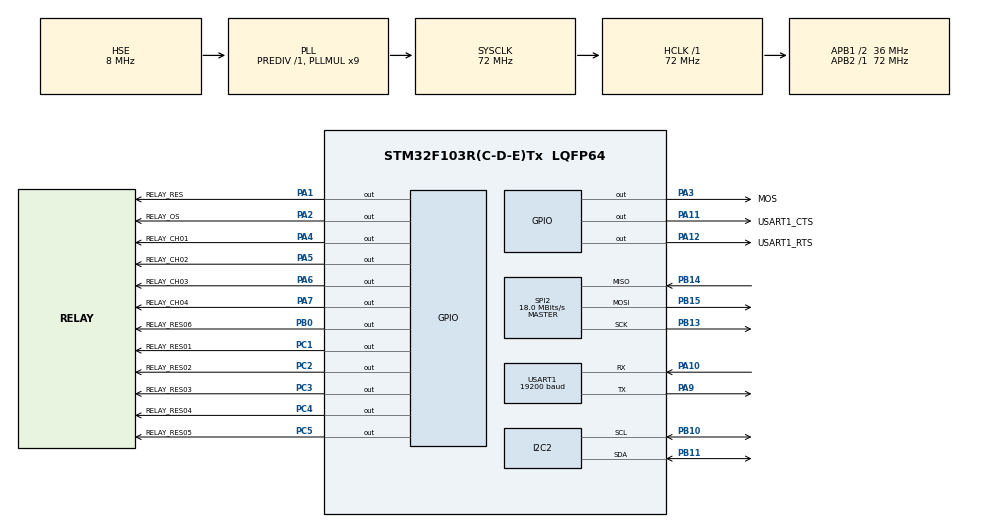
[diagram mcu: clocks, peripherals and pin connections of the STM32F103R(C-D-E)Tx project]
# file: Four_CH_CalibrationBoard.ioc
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Mcu.Family=STM32F1
Mcu.Name=STM32F103R(C-D-E)Tx
Mcu.Package=LQFP64
NVIC.PriorityGroup=NVIC_PRIORITYGROUP_4
NVIC.TIM7_IRQn=true\:0\:0\:false\:false\:true\:true\:true\:true
NVIC.USART1_IRQn=true\:0\:0\:false\:false\:true\:true\:true\:true
PA1.GPIO_Label=RELAY_RES 
PA1.GPIO_PuPd=GPIO_NOPULL
PA1.PinState=GPIO_PIN_SET
PA1.Signal=GPIO_Output
PA10.Mode=Asynchronous
PA10.Signal=USART1_RX
PA11.GPIO_Label=USART1_CTS
PA11.Signal=GPIO_Output
PA12.GPIO_Label=USART1_RTS
PA12.Signal=GPIO_Output
PA13.Mode=Serial_Wire
PA13.Signal=SYS_JTMS-SWDIO
PA14.Mode=Serial_Wire
PA14.Signal=SYS_JTCK-SWCLK
PA2.GPIO_Label=RELAY_OS 
PA2.Signal=GPIO_Output
PA3.GPIO_Label=MOS 
PA3.Signal=GPIO_Output
PA4.GPIO_Label=RELAY_CH01 
PA4.Signal=GPIO_Output
PA5.GPIO_Label=RELAY_CH02 
PA5.Signal=GPIO_Output
PA6.GPIO_Label=RELAY_CH03 
PA6.Signal=GPIO_Output
PA7.GPIO_Label=RELAY_CH04 
PA7.Signal=GPIO_Output
PA9.Mode=Asynchronous
PA9.Signal=USART1_TX
PB0.GPIO_Label=RELAY_RES06 
PB0.Signal=GPIO_Output
PB10.Mode=I2C
PB10.Signal=I2C2_SCL
PB11.Mode=I2C
PB11.Signal=I2C2_SDA
PB13.Mode=Full_Duplex_Master
PB13.Signal=SPI2_SCK
PB14.Mode=Full_Duplex_Master
PB14.Signal=SPI2_MISO
PB15.Mode=Full_Duplex_Master
PB15.Signal=SPI2_MOSI
PC1.GPIO_Label=RELAY_RES01 
PC1.Signal=GPIO_Output
PC2.GPIO_Label=RELAY_RES02 
PC2.Signal=GPIO_Output
PC3.GPIO_Label=RELAY_RES03 
PC3.Signal=GPIO_Output
PC4.GPIO_Label=RELAY_RES04
PC4.Signal=GPIO_Output
PC5.GPIO_Label=RELAY_RES05
PC5.Signal=GPIO_Output
PD0-OSC_IN.Mode=HSE-External-Oscillator
PD0-OSC_IN.Signal=RCC_OSC_IN
PD1-OSC_OUT.Mode=HSE-External-Oscillator
PD1-OSC_OUT.Signal=RCC_OSC_OUT
ProjectManager.HeapSize=0x200
ProjectManager.StackSize=0x400
ProjectManager.TargetToolchain=STM32CubeIDE
RCC.AHBFreq_Value=72000000
RCC.APB1CLKDivider=RCC_HCLK_DIV2
RCC.APB1Freq_Value=36000000
RCC.APB1TimFreq_Value=72000000
RCC.APB2Freq_Value=72000000
RCC.APB2TimFreq_Value=72000000
RCC.HCLKFreq_Value=72000000
RCC.PLLMUL=RCC_PLL_MUL9
RCC.PLLSourceVirtual=RCC_PLLSOURCE_HSE
RCC.SYSCLKFreq_VALUE=72000000
RCC.SYSCLKSource=RCC_SYSCLKSOURCE_PLLCLK
RCC.USBFreq_Value=72000000
SPI2.CalculateBaudRate=18.0 MBits/s
SPI2.Direction=SPI_DIRECTION_2LINES
SPI2.Mode=SPI_MODE_MASTER
SPI2.VirtualType=VM_MASTER
TIM7.AutoReloadPreload=TIM_AUTORELOAD_PRELOAD_ENABLE
USART1.BaudRate=19200
USART1.Parity=PARITY_EVEN
USART1.VirtualMode=VM_ASYNC
USART1.WordLength=WORDLENGTH_9B
VP_TIM7_VS_ClockSourceINT.Mode=Enable_Timer
board=custom

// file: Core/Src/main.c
/* USER CODE BEGIN Header */
/**
  ******************************************************************************
  * @file           : main.c
  * @brief          : Main program body
  ******************************************************************************
  * @attention
  *
  * Copyright (c) 2025 STMicroelectronics.
  * All rights reserved.
  *
  * This software is licensed under terms that can be found in the LICENSE file
  * in the root directory of this software component.
  * If no LICENSE file comes with this software, it is provided AS-IS.
  *
  ******************************************************************************
  */
/* USER CODE END Header */
#include "main.h"
#include "i2c.h"
#include "spi.h"
#include "tim.h"
#include "usart.h"
#include "gpio.h"

/* USER CODE BEGIN Includes */
#include "mb.h"
#include "command.h"
#include "hc_smu_control.h"

/* USER CODE END Includes */

/* USER CODE BEGIN PV */
HOLD_REG* volatile sys_set = (HOLD_REG*)&REG_HOLD_BUF[0];
INPUT_REG* volatile sys_dat = (INPUT_REG*)&REG_INPUT_BUF[0];

/* USER CODE END PV */

void SystemClock_Config(void);

int main(void)
{

  /* MCU Configuration--------------------------------------------------------*/

  /* Reset of all peripherals, Initializes the Flash interface and the Systick. */
  HAL_Init();

  /* Configure the system clock */
  SystemClock_Config();

  /* Initialize all configured peripherals */
  MX_GPIO_Init();
  MX_USART1_UART_Init();
  MX_I2C2_Init();
  MX_SPI2_Init();
  MX_TIM7_Init();
  /* USER CODE BEGIN 2 */

	// Modbus初始化
	eMBInit(MB_RTU, 1, 0x01, 115200, MB_PAR_EVEN);
	// 使能Modbus
	eMBEnable();

	// 初始化数据结构
	init_DATA_Struct(sys_dat);

	// HC-SMU控制模块初始化
	HC_SMU_Init();

  /* USER CODE END 2 */

  /* Infinite loop */
  while (1)
  {

    /* USER CODE BEGIN 3 */
	  // Modbus协议处理
	  eMBPoll();

	  // 命令处理任务(检测寄存器变化并执行控制)
	  CMD_ProcessTask();
  }
  /* USER CODE END 3 */
}

void SystemClock_Config(void)
{
  RCC_OscInitTypeDef RCC_OscInitStruct = {0};
  RCC_ClkInitTypeDef RCC_ClkInitStruct = {0};

  /** Initializes the RCC Oscillators according to the specified parameters
  * in the RCC_OscInitTypeDef structure.
  */
  RCC_OscInitStruct.OscillatorType = RCC_OSCILLATORTYPE_HSE;
  RCC_OscInitStruct.HSEState = RCC_HSE_ON;
  RCC_OscInitStruct.HSEPredivValue = RCC_HSE_PREDIV_DIV1;
  RCC_OscInitStruct.HSIState = RCC_HSI_ON;
  RCC_OscInitStruct.PLL.PLLState = RCC_PLL_ON;
  RCC_OscInitStruct.PLL.PLLSource = RCC_PLLSOURCE_HSE;
  RCC_OscInitStruct.PLL.PLLMUL = RCC_PLL_MUL9;
  if (HAL_RCC_OscConfig(&RCC_OscInitStruct) != HAL_OK)
  {
    Error_Handler();
  }

  /** Initializes the CPU, AHB and APB buses clocks
  */
  RCC_ClkInitStruct.ClockType = RCC_CLOCKTYPE_HCLK|RCC_CLOCKTYPE_SYSCLK
                              |RCC_CLOCKTYPE_PCLK1|RCC_CLOCKTYPE_PCLK2;
  RCC_ClkInitStruct.SYSCLKSource = RCC_SYSCLKSOURCE_PLLCLK;
  RCC_ClkInitStruct.AHBCLKDivider = RCC_SYSCLK_DIV1;
  RCC_ClkInitStruct.APB1CLKDivider = RCC_HCLK_DIV2;
  RCC_ClkInitStruct.APB2CLKDivider = RCC_HCLK_DIV1;

  if (HAL_RCC_ClockConfig(&RCC_ClkInitStruct, FLASH_LATENCY_2) != HAL_OK)
  {
    Error_Handler();
  }
}

void Error_Handler(void)
{
  __disable_irq();
  while (1)
  {
  }
}
